AUTOSAR XML (schema 00051)
standard types defined: boolean, uint8, uint16, uint32, boolean_DataConstr, boolean_CompuMethod
package /PortInterfaces
  6 x sender receiver interface:
    LockCmd
      data LockCmd: type=uint8
    LockReq
      data LockReq: type=uint8
    VehSpd
      data VehSpd: type=uint16
    VehSpdVld
      data VehSpdVld: type=uint8
    FrLeDoorState
      data FrLeDoorState: type=uint8
    ReLeDoorState
      data ReLeDoorState: type=uint8
package /Constants
  6 x constant specification, all with value-spec=0:
    LockCmd_IV
    LockReq_IV
    VehSpd_IV
    VehSpdVld_IV
    FrLeDoorState_IV
    ReLeDoorState_IV
package /ComponentTypes
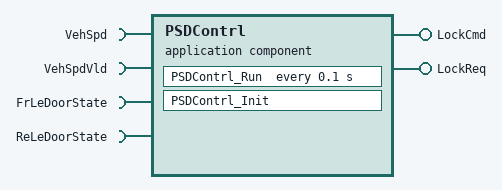
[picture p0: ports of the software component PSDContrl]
  application sw component type PSDContrl
    provide port LockCmd: nonqueued-sender-com-spec{data-element=LockCmd, init-value=constant-reference=LockCmd_IV}, provided-interface=LockCmd
    provide port LockReq: nonqueued-sender-com-spec{data-element=LockReq, init-value=constant-reference=LockReq_IV}, provided-interface=LockReq
    4 x require port:
      VehSpd: nonqueued-receiver-com-spec{data-element=VehSpd, init-value=constant-reference=VehSpd_IV}, required-interface=VehSpd
      VehSpdVld: nonqueued-receiver-com-spec{data-element=VehSpdVld, init-value=constant-reference=VehSpdVld_IV}, required-interface=VehSpdVld
      FrLeDoorState: nonqueued-receiver-com-spec{data-element=FrLeDoorState, init-value=constant-reference=FrLeDoorState_IV}, required-interface=FrLeDoorState
      ReLeDoorState: nonqueued-receiver-com-spec{data-element=ReLeDoorState, init-value=constant-reference=ReLeDoorState_IV}, required-interface=ReLeDoorState
    behavior PSDContrl_InternalBehavior
      exclusive area ExampleExclusiveArea
      init event IT_PSDContrl_Init: start-on-event=PSDContrl_Init
      timing event TMT_PSDContrl_Run: start-on-event=PSDContrl_Run, period=0.1
      port-api-options:
        enable-take-address=false, indirect-api=false, port=FrLeDoorState
        enable-take-address=false, indirect-api=false, port=LockCmd
        enable-take-address=false, indirect-api=false, port=LockReq
        enable-take-address=false, indirect-api=false, port=ReLeDoorState
        enable-take-address=false, indirect-api=false, port=VehSpd
        enable-take-address=false, indirect-api=false, port=VehSpdVld
      runnable PSDContrl_Init
      runnable PSDContrl_Run
        data-receive-point-by-arguments:
          4 x access:
            REC_VehSpd_VehSpd: accessed-variable=VehSpd.VehSpd
            REC_VehSpdVld_VehSpdVld: accessed-variable=VehSpdVld.VehSpdVld
            REC_FrLeDoorState_FrLeDoorState: accessed-variable=FrLeDoorState.FrLeDoorState
            REC_ReLeDoorState_ReLeDoorState: accessed-variable=ReLeDoorState.ReLeDoorState
        data-send-points:
          access SEND_LockCmd_LockCmd: accessed-variable=LockCmd.LockCmd
          access SEND_LockReq_LockReq: accessed-variable=LockReq.LockReq
  swc implementation PSDContrl_Implementation: behavior=PSDContrl_InternalBehavior
